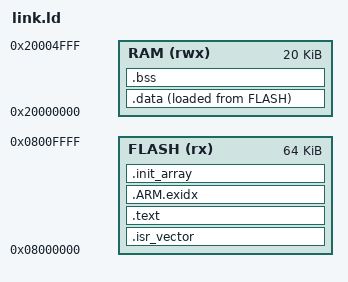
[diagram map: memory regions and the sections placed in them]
/* Bare-metal linker script: STM32F103C8 (64 KiB flash, 20 KiB SRAM). */
ENTRY(Reset_Handler)
MEMORY
{
  FLASH (rx)  : ORIGIN = 0x08000000, LENGTH = 64K
  RAM   (rwx) : ORIGIN = 0x20000000, LENGTH = 20K
}
_estack = ORIGIN(RAM) + LENGTH(RAM);

SECTIONS
{
  .isr_vector : { . = ALIGN(4); KEEP(*(.isr_vector)) . = ALIGN(4); } > FLASH
  .text : { . = ALIGN(4); *(.text) *(.text*) *(.rodata) *(.rodata*) . = ALIGN(4); } > FLASH
  .ARM.exidx : { *(.ARM.exidx*) } > FLASH
  .init_array : { PROVIDE_HIDDEN(__init_array_start = .); KEEP(*(SORT(.init_array.*))) KEEP(*(.init_array*)) PROVIDE_HIDDEN(__init_array_end = .); } > FLASH
  _sidata = LOADADDR(.data);
  .data : { . = ALIGN(4); _sdata = .; *(.data) *(.data*) . = ALIGN(4); _edata = .; } > RAM AT > FLASH
  .bss (NOLOAD) : { . = ALIGN(4); _sbss = .; *(.bss) *(.bss*) *(COMMON) . = ALIGN(4); _ebss = .; } > RAM
}
